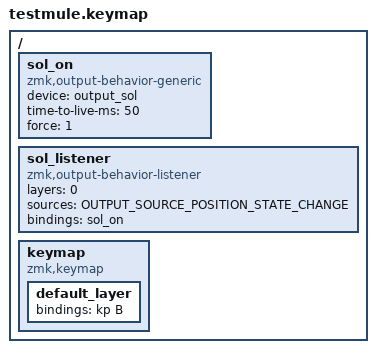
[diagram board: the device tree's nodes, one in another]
#define OUTPUT_SOURCE_LAYER_STATE_CHANGE        1
#define OUTPUT_SOURCE_POSITION_STATE_CHANGE     2
#define OUTPUT_SOURCE_KEYCODE_STATE_CHANGE      3
#define OUTPUT_SOURCE_MOUSE_BUTTON_STATE_CHANGE 4
#define OUTPUT_SOURCE_MOUSE_WHEEL_STATE_CHANGE  5
#define OUTPUT_SOURCE_TRANSPORT                 6

#include <behaviors.dtsi>
#include <dt-bindings/zmk/keys.h>

/ {
	sol_on: sol_on {
		compatible = "zmk,output-behavior-generic"; 
		#binding-cells = <0>;
		device = <&output_sol>; 
		time-to-live-ms = <50>; // Durée d'activation du pin (dwell time)
		force = <1>;
	};

	sol_listener {
		compatible = "zmk,output-behavior-listener";
		layers = < 0 >;
		sources = < OUTPUT_SOURCE_POSITION_STATE_CHANGE >;
	
		bindings = < &sol_on >;
	};
	
	keymap {
		compatible = "zmk,keymap";
		
		default_layer {
			bindings = <
			&kp B
			>;
		};
	};
};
